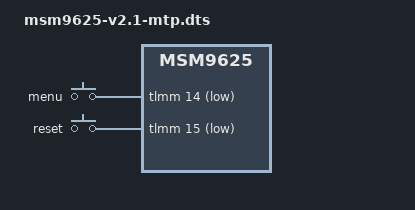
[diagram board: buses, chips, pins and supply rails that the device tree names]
// SPDX-License-Identifier: BSD-3-Clause

#include <skeleton64.dtsi>
#include <lk2nd.dtsi>

/ {
	qcom,msm-id = <QCOM_ID_MDM9625 7 0x20001>, <QCOM_ID_MDM9625M 7 0x20001>, <QCOM_ID_MDM9225 7 0x20001>,
		      <QCOM_ID_MDM9225M 7 0x20001>, <151 7 0x20001>, <148 7 0x20001>,
		      <173 7 0x20001>, <174 7 0x20001>, <175 7 0x20001>;
};

&lk2nd {
	tp-link-m7350-v3 {
		model = "TP-Link M7350";
		compatible = "tplink,m7350-v3";

		gpio-keys {
			compatible = "gpio-keys";
			
			menu {
				lk2nd,code = <KEY_HOME>;
				gpios = <&tlmm 14 (GPIO_ACTIVE_LOW | GPIO_PULL_UP)>;
			};

			reset {
				lk2nd,code = <KEY_HOME>;
				gpios = <&tlmm 15 (GPIO_ACTIVE_LOW | GPIO_PULL_UP)>;
			};
		};
	};
};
